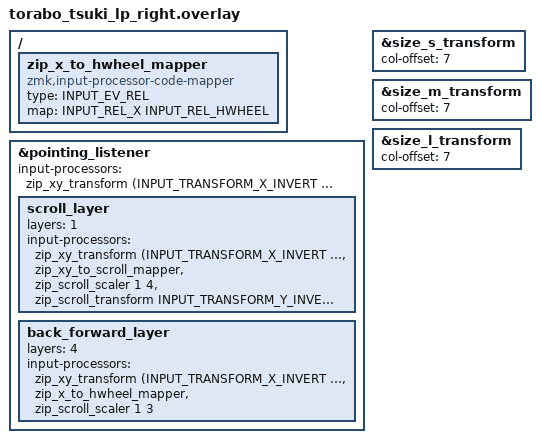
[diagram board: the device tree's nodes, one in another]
#include "torabo_tsuki_lp.dtsi"
#include <input/processors.dtsi>
#include <dt-bindings/zmk/input_transform.h>
#include <zephyr/dt-bindings/input/input-event-codes.h>

/ {
    zip_x_to_hwheel_mapper: zip_x_to_hwheel_mapper {
        compatible = "zmk,input-processor-code-mapper";
        #input-processor-cells = <0>;
        type = <INPUT_EV_REL>;
        map = <INPUT_REL_X INPUT_REL_HWHEEL>;
    };
};

&pointing_listener {
    input-processors = <&zip_xy_transform (INPUT_TRANSFORM_X_INVERT | INPUT_TRANSFORM_Y_INVERT)>;

    scroll_layer {
        layers = <1>;
        input-processors = <&zip_xy_transform (INPUT_TRANSFORM_X_INVERT | INPUT_TRANSFORM_Y_INVERT) &zip_xy_to_scroll_mapper &zip_scroll_scaler 1 4 &zip_scroll_transform INPUT_TRANSFORM_Y_INVERT>;
    };

    back_forward_layer {
        layers = <4>;
        input-processors = <&zip_xy_transform (INPUT_TRANSFORM_X_INVERT | INPUT_TRANSFORM_Y_INVERT) &zip_x_to_hwheel_mapper &zip_scroll_scaler 1 3>;
    };
};

&size_s_transform {
    col-offset = <7>;
};

&size_m_transform {
    col-offset = <7>;
};

&size_l_transform {
    col-offset = <7>;
};
